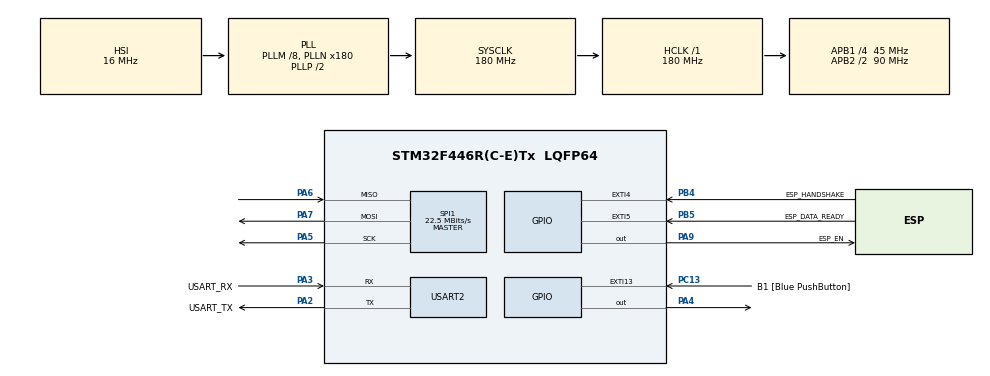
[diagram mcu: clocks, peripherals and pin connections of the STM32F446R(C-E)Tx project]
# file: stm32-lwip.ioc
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Dma.Request0=USART2_RX
Dma.Request1=USART2_TX
Dma.Request2=SPI1_RX
Dma.Request3=SPI1_TX
Dma.SPI1_RX.2.Direction=DMA_PERIPH_TO_MEMORY
Dma.SPI1_RX.2.FIFOMode=DMA_FIFOMODE_DISABLE
Dma.SPI1_RX.2.Instance=DMA2_Stream0
Dma.SPI1_RX.2.MemDataAlignment=DMA_MDATAALIGN_BYTE
Dma.SPI1_RX.2.MemInc=DMA_MINC_ENABLE
Dma.SPI1_RX.2.Mode=DMA_NORMAL
Dma.SPI1_RX.2.PeriphDataAlignment=DMA_PDATAALIGN_BYTE
Dma.SPI1_RX.2.PeriphInc=DMA_PINC_DISABLE
Dma.SPI1_RX.2.Priority=DMA_PRIORITY_LOW
Dma.SPI1_TX.3.Direction=DMA_MEMORY_TO_PERIPH
Dma.SPI1_TX.3.FIFOMode=DMA_FIFOMODE_DISABLE
Dma.SPI1_TX.3.Instance=DMA2_Stream3
Dma.SPI1_TX.3.MemDataAlignment=DMA_MDATAALIGN_BYTE
Dma.SPI1_TX.3.MemInc=DMA_MINC_ENABLE
Dma.SPI1_TX.3.Mode=DMA_NORMAL
Dma.SPI1_TX.3.PeriphDataAlignment=DMA_PDATAALIGN_BYTE
Dma.SPI1_TX.3.PeriphInc=DMA_PINC_DISABLE
Dma.SPI1_TX.3.Priority=DMA_PRIORITY_LOW
Dma.USART2_RX.0.Direction=DMA_PERIPH_TO_MEMORY
Dma.USART2_RX.0.FIFOMode=DMA_FIFOMODE_DISABLE
Dma.USART2_RX.0.Instance=DMA1_Stream5
Dma.USART2_RX.0.MemDataAlignment=DMA_MDATAALIGN_BYTE
Dma.USART2_RX.0.MemInc=DMA_MINC_ENABLE
Dma.USART2_RX.0.Mode=DMA_NORMAL
Dma.USART2_RX.0.PeriphDataAlignment=DMA_PDATAALIGN_BYTE
Dma.USART2_RX.0.PeriphInc=DMA_PINC_DISABLE
Dma.USART2_RX.0.Priority=DMA_PRIORITY_LOW
Dma.USART2_TX.1.Direction=DMA_MEMORY_TO_PERIPH
Dma.USART2_TX.1.FIFOMode=DMA_FIFOMODE_DISABLE
Dma.USART2_TX.1.Instance=DMA1_Stream6
Dma.USART2_TX.1.MemDataAlignment=DMA_MDATAALIGN_BYTE
Dma.USART2_TX.1.MemInc=DMA_MINC_ENABLE
Dma.USART2_TX.1.Mode=DMA_NORMAL
Dma.USART2_TX.1.PeriphDataAlignment=DMA_PDATAALIGN_BYTE
Dma.USART2_TX.1.PeriphInc=DMA_PINC_DISABLE
Dma.USART2_TX.1.Priority=DMA_PRIORITY_LOW
FREERTOS.HEAP_NUMBER=4
FREERTOS.MEMORY_ALLOCATION=2
FREERTOS.Tasks01=defaultTask,0,256,StartDefaultTask,Default,NULL,Static,defaultTaskBuffer,defaultTaskControlBlock
FREERTOS.configCHECK_FOR_STACK_OVERFLOW=2
FREERTOS.configENABLE_FPU=1
FREERTOS.configGENERATE_RUN_TIME_STATS=1
FREERTOS.configRECORD_STACK_HIGH_ADDRESS=1
FREERTOS.configTOTAL_HEAP_SIZE=90000
FREERTOS.configUSE_COUNTING_SEMAPHORES=1
FREERTOS.configUSE_NEWLIB_REENTRANT=1
FREERTOS.configUSE_RECURSIVE_MUTEXES=1
FREERTOS.configUSE_TRACE_FACILITY=1
Mcu.Family=STM32F4
Mcu.Name=STM32F446R(C-E)Tx
Mcu.Package=LQFP64
NVIC.DMA1_Stream5_IRQn=true\:5\:0\:false\:false\:true\:true\:false\:true
NVIC.DMA1_Stream6_IRQn=true\:5\:0\:false\:false\:true\:true\:false\:true
NVIC.DMA2_Stream0_IRQn=true\:5\:0\:false\:false\:true\:true\:false\:true
NVIC.DMA2_Stream3_IRQn=true\:5\:0\:false\:false\:true\:true\:false\:true
NVIC.EXTI15_10_IRQn=true\:5\:0\:false\:false\:true\:true\:true\:true
NVIC.EXTI4_IRQn=true\:5\:0\:false\:false\:true\:true\:true\:true
NVIC.EXTI9_5_IRQn=true\:5\:0\:false\:false\:true\:true\:true\:true
NVIC.PriorityGroup=NVIC_PRIORITYGROUP_4
NVIC.SPI1_IRQn=true\:5\:0\:false\:false\:true\:true\:true\:true
NVIC.USART2_IRQn=true\:5\:0\:false\:false\:true\:true\:true\:true
PA13.GPIO_Label=TMS
PA13.Mode=Trace_Asynchronous_SW
PA13.Signal=SYS_JTMS-SWDIO
PA14.GPIO_Label=TCK
PA14.Mode=Trace_Asynchronous_SW
PA14.Signal=SYS_JTCK-SWCLK
PA2.GPIO_Label=USART_TX
PA2.Mode=Asynchronous
PA2.Signal=USART2_TX
PA3.GPIO_Label=USART_RX
PA3.Mode=Asynchronous
PA3.Signal=USART2_RX
PA4.GPIO_PuPd=GPIO_PULLUP
PA4.GPIO_Speed=GPIO_SPEED_FREQ_MEDIUM
PA4.PinState=GPIO_PIN_SET
PA4.Signal=GPIO_Output
PA5.GPIO_PuPd=GPIO_PULLDOWN
PA5.Mode=Full_Duplex_Master
PA5.Signal=SPI1_SCK
PA6.GPIO_PuPd=GPIO_PULLUP
PA6.Mode=Full_Duplex_Master
PA6.Signal=SPI1_MISO
PA7.GPIO_PuPd=GPIO_PULLUP
PA7.Mode=Full_Duplex_Master
PA7.Signal=SPI1_MOSI
PA9.GPIO_Label=ESP_EN
PA9.Signal=GPIO_Output
PB3.GPIO_Label=SWO
PB3.Mode=Trace_Asynchronous_SW
PB3.Signal=SYS_JTDO-SWO
PB4.GPIO_Label=ESP_HANDSHAKE
PB4.Signal=GPXTI4
PB5.GPIO_Label=ESP_DATA_READY
PB5.Signal=GPXTI5
PC13.GPIO_Label=B1 [Blue PushButton]
PC13.GPIO_ModeDefaultEXTI=GPIO_MODE_IT_FALLING
PC13.Signal=GPXTI13
PC14-OSC32_IN.Signal=RCC_OSC32_IN
PC15-OSC32_OUT.Signal=RCC_OSC32_OUT
PH0-OSC_IN.Signal=RCC_OSC_IN
PH1-OSC_OUT.Signal=RCC_OSC_OUT
ProjectManager.HeapSize=0x200
ProjectManager.StackSize=0x400
ProjectManager.TargetToolchain=STM32CubeIDE
RCC.AHBFreq_Value=180000000
RCC.APB1CLKDivider=RCC_HCLK_DIV4
RCC.APB1Freq_Value=45000000
RCC.APB1TimFreq_Value=90000000
RCC.APB2CLKDivider=RCC_HCLK_DIV2
RCC.APB2Freq_Value=90000000
RCC.APB2TimFreq_Value=180000000
RCC.CortexFreq_Value=180000000
RCC.FLatency-AdvancedSettings=FLASH_LATENCY_5
RCC.HCLKFreq_Value=180000000
RCC.HSE_VALUE=8000000
RCC.HSI_VALUE=16000000
RCC.LSE_VALUE=32768
RCC.PLLM=8
RCC.PLLN=180
RCC.SYSCLKFreq_VALUE=180000000
RCC.SYSCLKSource=RCC_SYSCLKSOURCE_PLLCLK
RCC.USBFreq_Value=180000000
RCC.VCOOutputFreq_Value=360000000
SPI1.BaudRatePrescaler=SPI_BAUDRATEPRESCALER_4
SPI1.CLKPhase=SPI_PHASE_2EDGE
SPI1.CLKPolarity=SPI_POLARITY_LOW
SPI1.CalculateBaudRate=22.5 MBits/s
SPI1.Direction=SPI_DIRECTION_2LINES
SPI1.Mode=SPI_MODE_MASTER
SPI1.VirtualType=VM_MASTER
USART2.VirtualMode=VM_ASYNC
VP_CRC_VS_CRC.Mode=CRC_Activate
VP_FREERTOS_VS_CMSIS_V1.Mode=CMSIS_V1
VP_TIM6_VS_ClockSourceINT.Mode=Enable_Timer
board=NUCLEO-F446RE

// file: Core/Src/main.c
/* USER CODE BEGIN Header */
/**
  ******************************************************************************
  * @file           : main.c
  * @brief          : Main program body
  ******************************************************************************
  * @attention
  *
  * <h2><center>&copy; Copyright (c) 2021 STMicroelectronics.
  * All rights reserved.</center></h2>
  *
  * This software component is licensed by ST under BSD 3-Clause license,
  * the "License"; You may not use this file except in compliance with the
  * License. You may obtain a copy of the License at:
  *                        opensource.org/licenses/BSD-3-Clause
  *
  ******************************************************************************
  */
/* USER CODE END Header */
#include "main.h"
#include "cmsis_os.h"
#include "crc.h"
#include "dma.h"
#include "spi.h"
#include "tim.h"
#include "usart.h"
#include "gpio.h"

/* USER CODE BEGIN Includes */
#include <stdio.h>
#include "cli_startup.h"
/* USER CODE END Includes */

void SystemClock_Config(void);
void MX_FREERTOS_Init(void);

int main(void)
{
  /* USER CODE BEGIN 1 */
	// Turn off buffers, so I/O occurs immediately
		setbuf(stdout, NULL);
		assert(setvbuf(stdout, NULL, _IONBF, 0) ==0);
		assert(setvbuf(stdin, NULL, _IONBF, 0) ==0);
		assert(setvbuf(stderr, NULL, _IONBF, 0)==0);

  /* USER CODE END 1 */

  /* MCU Configuration--------------------------------------------------------*/

  /* Reset of all peripherals, Initializes the Flash interface and the Systick. */
  HAL_Init();

  /* USER CODE BEGIN Init */
  CoreDebug->DEMCR |= CoreDebug_DEMCR_TRCENA_Msk;
  DWT->CYCCNT = 0;
  DWT->CTRL |= DWT_CTRL_CYCCNTENA_Msk;
  /* USER CODE END Init */

  /* Configure the system clock */
  SystemClock_Config();

  /* Initialize all configured peripherals */
  MX_GPIO_Init();
  MX_CRC_Init();
  MX_SPI1_Init();
  MX_TIM6_Init();
  MX_DMA_Init();
  MX_USART2_UART_Init();
  /* USER CODE BEGIN 2 */

  printf("starting...\r\n");
  cli_startup();
  /* USER CODE END 2 */

  /* Call init function for freertos objects (in freertos.c) */
  MX_FREERTOS_Init();
  /* Start scheduler */
  osKernelStart();

  /* We should never get here as control is now taken by the scheduler */
  /* Infinite loop */
  while (1)
  {

  }
}

void SystemClock_Config(void)
{
  RCC_OscInitTypeDef RCC_OscInitStruct = {0};
  RCC_ClkInitTypeDef RCC_ClkInitStruct = {0};

  /** Configure the main internal regulator output voltage
  */
  __HAL_RCC_PWR_CLK_ENABLE();
  __HAL_PWR_VOLTAGESCALING_CONFIG(PWR_REGULATOR_VOLTAGE_SCALE1);
  /** Initializes the RCC Oscillators according to the specified parameters
  * in the RCC_OscInitTypeDef structure.
  */
  RCC_OscInitStruct.OscillatorType = RCC_OSCILLATORTYPE_HSI;
  RCC_OscInitStruct.HSIState = RCC_HSI_ON;
  RCC_OscInitStruct.HSICalibrationValue = RCC_HSICALIBRATION_DEFAULT;
  RCC_OscInitStruct.PLL.PLLState = RCC_PLL_ON;
  RCC_OscInitStruct.PLL.PLLSource = RCC_PLLSOURCE_HSI;
  RCC_OscInitStruct.PLL.PLLM = 8;
  RCC_OscInitStruct.PLL.PLLN = 180;
  RCC_OscInitStruct.PLL.PLLP = RCC_PLLP_DIV2;
  RCC_OscInitStruct.PLL.PLLQ = 2;
  RCC_OscInitStruct.PLL.PLLR = 2;
  if (HAL_RCC_OscConfig(&RCC_OscInitStruct) != HAL_OK)
  {
    Error_Handler();
  }
  /** Activate the Over-Drive mode
  */
  if (HAL_PWREx_EnableOverDrive() != HAL_OK)
  {
    Error_Handler();
  }
  /** Initializes the CPU, AHB and APB buses clocks
  */
  RCC_ClkInitStruct.ClockType = RCC_CLOCKTYPE_HCLK|RCC_CLOCKTYPE_SYSCLK
                              |RCC_CLOCKTYPE_PCLK1|RCC_CLOCKTYPE_PCLK2;
  RCC_ClkInitStruct.SYSCLKSource = RCC_SYSCLKSOURCE_PLLCLK;
  RCC_ClkInitStruct.AHBCLKDivider = RCC_SYSCLK_DIV1;
  RCC_ClkInitStruct.APB1CLKDivider = RCC_HCLK_DIV4;
  RCC_ClkInitStruct.APB2CLKDivider = RCC_HCLK_DIV2;

  if (HAL_RCC_ClockConfig(&RCC_ClkInitStruct, FLASH_LATENCY_5) != HAL_OK)
  {
    Error_Handler();
  }
}

void Error_Handler(void)
{
  __disable_irq();
  while (1)
  {
  }
}

/************************ (C) COPYRIGHT STMicroelectronics *****END OF FILE****/

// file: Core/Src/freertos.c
/* USER CODE BEGIN Header */
/**
 ******************************************************************************
 * File Name          : freertos.c
 * Description        : Code for freertos applications
 ******************************************************************************
 * @attention
 *
 * <h2><center>&copy; Copyright (c) 2021 STMicroelectronics.
 * All rights reserved.</center></h2>
 *
 * This software component is licensed by ST under Ultimate Liberty license
 * SLA0044, the "License"; You may not use this file except in compliance with
 * the License. You may obtain a copy of the License at:
 *                             www.st.com/SLA0044
 *
 ******************************************************************************
 */
/* USER CODE END Header */

#include "FreeRTOS.h"
#include "task.h"
#include "main.h"
#include "cmsis_os.h"

osThreadId defaultTaskHandle;
uint32_t defaultTaskBuffer[ 256 ];
osStaticThreadDef_t defaultTaskControlBlock;

void StartDefaultTask(void const * argument);

void MX_FREERTOS_Init(void); /* (MISRA C 2004 rule 8.1) */

/* GetIdleTaskMemory prototype (linked to static allocation support) */
void vApplicationGetIdleTaskMemory( StaticTask_t **ppxIdleTaskTCBBuffer, StackType_t **ppxIdleTaskStackBuffer, uint32_t *pulIdleTaskStackSize );

/* Hook prototypes */
void configureTimerForRunTimeStats(void);
unsigned long getRunTimeCounterValue(void);
void vApplicationStackOverflowHook(xTaskHandle xTask, signed char *pcTaskName);

/* USER CODE BEGIN 1 */
/* Functions needed when configGENERATE_RUN_TIME_STATS is on */
__weak void configureTimerForRunTimeStats(void) {

}

__weak unsigned long getRunTimeCounterValue(void) {
	return 0;
}
/* USER CODE END 1 */

/* USER CODE BEGIN 4 */
__weak void vApplicationStackOverflowHook(xTaskHandle xTask, signed char *pcTaskName)
{
   /* Run time stack overflow checking is performed if
   configCHECK_FOR_STACK_OVERFLOW is defined to 1 or 2. This hook function is
   called if a stack overflow is detected. */
}
/* USER CODE END 4 */

/* USER CODE BEGIN GET_IDLE_TASK_MEMORY */
static StaticTask_t xIdleTaskTCBBuffer;
static StackType_t xIdleStack[configMINIMAL_STACK_SIZE];

void vApplicationGetIdleTaskMemory(StaticTask_t **ppxIdleTaskTCBBuffer,
		StackType_t **ppxIdleTaskStackBuffer, uint32_t *pulIdleTaskStackSize) {
	*ppxIdleTaskTCBBuffer = &xIdleTaskTCBBuffer;
	*ppxIdleTaskStackBuffer = &xIdleStack[0];
	*pulIdleTaskStackSize = configMINIMAL_STACK_SIZE;
	/* place for user code */
}
/* USER CODE END GET_IDLE_TASK_MEMORY */

void MX_FREERTOS_Init(void) {

  /* Create the thread(s) */
  /* definition and creation of defaultTask */
  osThreadStaticDef(defaultTask, StartDefaultTask, osPriorityNormal, 0, 256, defaultTaskBuffer, &defaultTaskControlBlock);
  defaultTaskHandle = osThreadCreate(osThread(defaultTask), NULL);

}

void StartDefaultTask(void const * argument)
{
  /* USER CODE BEGIN StartDefaultTask */
	hosted_initialize();

	/* Infinite loop */
	for (;;) {
		osDelay(1000);
	}
  /* USER CODE END StartDefaultTask */
}

/************************ (C) COPYRIGHT STMicroelectronics *****END OF FILE****/
